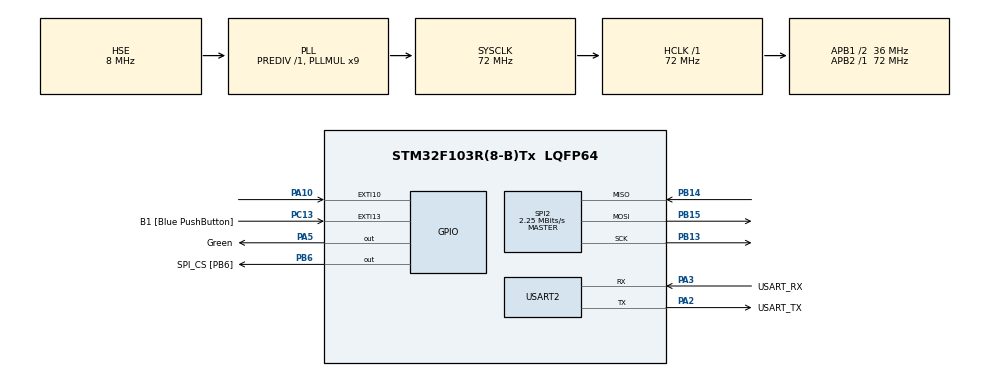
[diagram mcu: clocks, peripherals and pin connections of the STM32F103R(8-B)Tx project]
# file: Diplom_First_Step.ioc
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Dma.Request0=SPI2_RX
Dma.SPI2_RX.0.Direction=DMA_PERIPH_TO_MEMORY
Dma.SPI2_RX.0.Instance=DMA1_Channel4
Dma.SPI2_RX.0.MemDataAlignment=DMA_MDATAALIGN_HALFWORD
Dma.SPI2_RX.0.MemInc=DMA_MINC_ENABLE
Dma.SPI2_RX.0.Mode=DMA_NORMAL
Dma.SPI2_RX.0.PeriphDataAlignment=DMA_PDATAALIGN_BYTE
Dma.SPI2_RX.0.PeriphInc=DMA_PINC_DISABLE
Dma.SPI2_RX.0.Priority=DMA_PRIORITY_LOW
FREERTOS.Tasks01=defaultTask,0,2048,ADXL345_Data_Collector_Task,Default,NULL,Dynamic,NULL,NULL
FREERTOS.configTOTAL_HEAP_SIZE=16384
FREERTOS.configUSE_COUNTING_SEMAPHORES=1
FREERTOS.configUSE_NEWLIB_REENTRANT=1
Mcu.Family=STM32F1
Mcu.Name=STM32F103R(8-B)Tx
Mcu.Package=LQFP64
NVIC.DMA1_Channel4_IRQn=true\:5\:0\:false\:false\:true\:true\:false\:true
NVIC.EXTI15_10_IRQn=true\:5\:0\:false\:false\:true\:true\:true\:true
NVIC.PriorityGroup=NVIC_PRIORITYGROUP_4
NVIC.SPI2_IRQn=true\:5\:0\:false\:false\:true\:true\:true\:true
NVIC.TIM4_IRQn=true\:15\:0\:false\:false\:true\:false\:false\:true
NVIC.TimeBase=TIM4_IRQn
NVIC.TimeBaseIP=TIM4
NVIC.USART2_IRQn=true\:5\:0\:false\:false\:true\:true\:true\:true
PA10.Signal=GPXTI10
PA13.GPIO_Label=TMS
PA13.Mode=Serial_Wire
PA13.Signal=SYS_JTMS-SWDIO
PA14.GPIO_Label=TCK
PA14.Mode=Serial_Wire
PA14.Signal=SYS_JTCK-SWCLK
PA2.GPIO_Label=USART_TX
PA2.GPIO_Mode=GPIO_MODE_AF_PP
PA2.GPIO_PuPd=GPIO_NOPULL
PA2.GPIO_Speed=GPIO_SPEED_FREQ_LOW
PA2.Mode=Asynchronous
PA2.Signal=USART2_TX
PA3.GPIO_Label=USART_RX
PA3.GPIO_Mode=GPIO_MODE_AF_PP
PA3.GPIO_PuPd=GPIO_NOPULL
PA3.GPIO_Speed=GPIO_SPEED_FREQ_LOW
PA3.Mode=Asynchronous
PA3.Signal=USART2_RX
PA5.GPIO_Label=Green
PA5.Signal=GPIO_Output
PB13.Mode=Full_Duplex_Master
PB13.Signal=SPI2_SCK
PB14.Mode=Full_Duplex_Master
PB14.Signal=SPI2_MISO
PB15.Mode=Full_Duplex_Master
PB15.Signal=SPI2_MOSI
PB3.GPIO_Label=SWO
PB3.Signal=SYS_JTDO-TRACESWO
PB6.GPIO_Label=SPI_CS [PB6]
PB6.GPIO_ModeDefaultOutputPP=GPIO_MODE_OUTPUT_PP
PB6.GPIO_Speed=GPIO_SPEED_FREQ_HIGH
PB6.Signal=GPIO_Output
PC13-TAMPER-RTC.GPIO_Label=B1 [Blue PushButton]
PC13-TAMPER-RTC.GPIO_PuPd=GPIO_NOPULL
PC13-TAMPER-RTC.Signal=GPXTI13
PC14-OSC32_IN.Mode=LSE-External-Oscillator
PC14-OSC32_IN.Signal=RCC_OSC32_IN
PC15-OSC32_OUT.Mode=LSE-External-Oscillator
PC15-OSC32_OUT.Signal=RCC_OSC32_OUT
PD0-OSC_IN.Mode=HSE-External-Clock-Source
PD0-OSC_IN.Signal=RCC_OSC_IN
PD1-OSC_OUT.Mode=HSE-External-Clock-Source
PD1-OSC_OUT.Signal=RCC_OSC_OUT
ProjectManager.HeapSize=0x300
ProjectManager.StackSize=0x500
ProjectManager.TargetToolchain=STM32CubeIDE
RCC.AHBFreq_Value=72000000
RCC.APB1CLKDivider=RCC_HCLK_DIV2
RCC.APB1Freq_Value=36000000
RCC.APB1TimFreq_Value=72000000
RCC.APB2Freq_Value=72000000
RCC.APB2TimFreq_Value=72000000
RCC.HCLKFreq_Value=72000000
RCC.PLLMUL=RCC_PLL_MUL9
RCC.PLLSourceVirtual=RCC_PLLSOURCE_HSE
RCC.RTCClockSelection=RCC_RTCCLKSOURCE_LSE
RCC.SYSCLKFreq_VALUE=72000000
RCC.SYSCLKSource=RCC_SYSCLKSOURCE_PLLCLK
RCC.USBFreq_Value=72000000
SPI2.BaudRatePrescaler=SPI_BAUDRATEPRESCALER_16
SPI2.CLKPhase=SPI_PHASE_2EDGE
SPI2.CLKPolarity=SPI_POLARITY_HIGH
SPI2.CalculateBaudRate=2.25 MBits/s
SPI2.Direction=SPI_DIRECTION_2LINES
SPI2.Mode=SPI_MODE_MASTER
SPI2.VirtualType=VM_MASTER
USART2.VirtualMode=VM_ASYNC
VP_FREERTOS_VS_CMSIS_V1.Mode=CMSIS_V1
VP_SYS_VS_tim4.Mode=TIM4
board=NUCLEO-F103RB

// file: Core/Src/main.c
/* USER CODE BEGIN Header */
/**
  ******************************************************************************
  * @file           : main.c
  * @brief          : Main program body
  ******************************************************************************
  * @attention
  *
  * <h2><center>&copy; Copyright (c) 2021 STMicroelectronics.
  * All rights reserved.</center></h2>
  *
  * This software component is licensed by ST under BSD 3-Clause license,
  * the "License"; You may not use this file except in compliance with the
  * License. You may obtain a copy of the License at:
  *                        opensource.org/licenses/BSD-3-Clause
  *
  ******************************************************************************
  */
/*	Подключение акселерометра к микроконтроллеру
 * 	Акселерометр 	STM32F103RB - NUCLEO_F103RB
 * 		GND					   GND
 * 		VCC				   CN07 - PIN16
 * 		CS				   CN10 - PIN17
 * 	   INT1				   ------------
 * 	   INT2				   ------------
 * 	  	SDO				   CN10 - PIN13
 * 		SDA				   CN10 - PIN15
 * 		SCL				   CN10 - PIN11
 *
 */
/* USER CODE END Header */
#include "main.h"
#include "cmsis_os.h"

/* USER CODE BEGIN Includes */

/*	HAL_FREERTOS	*/
#include 	"uart_cobs_service.h"
#include 	"uart_freertos.h"
/*	Acceleration sensor	*/
#include 	"ADXL345.h"

#define 	Debug_Active

#ifdef 		Debug_Active
	#include 	"stdio.h"
#endif
/* USER CODE END Includes */

/* USER CODE BEGIN PD */

#define Length_Realization 		((uint16_t) 1024)

/* USER CODE END PD */

SPI_HandleTypeDef hspi2;

UART_HandleTypeDef huart2;

osThreadId defaultTaskHandle;
osSemaphoreId DataReloadInAccelerometerHandle;
/* USER CODE BEGIN PV */

ADXL_ConfigTypeDef_t 	ADXL;
uart_cobs_service_t 	Cobs_UART;

/* USER CODE END PV */

void SystemClock_Config(void);
static void MX_GPIO_Init(void);
static void MX_USART2_UART_Init(void);
static void MX_SPI2_Init(void);
void ADXL345_Data_Collector_Task(void const * argument);

/* USER CODE BEGIN PFP */
void ADXL345_Config(void);
void UART_Cobs_Config(void);
/* USER CODE END PFP */

int main(void)
{

  /* MCU Configuration--------------------------------------------------------*/

  /* Reset of all peripherals, Initializes the Flash interface and the Systick. */
  HAL_Init();

  /* Configure the system clock */
  SystemClock_Config();

  /* Initialize all configured peripherals */
  MX_GPIO_Init();
  MX_USART2_UART_Init();
  MX_SPI2_Init();
  /* USER CODE BEGIN 2 */
  /*	Deactivate IRQ then control Input and Output Transaction	*/
  /* USER CODE END 2 */

  /* Create the semaphores(s) */
  /* definition and creation of DataReloadInAccelerometer */
  osSemaphoreDef(DataReloadInAccelerometer);
  DataReloadInAccelerometerHandle = osSemaphoreCreate(osSemaphore(DataReloadInAccelerometer), 1);

  /* USER CODE BEGIN RTOS_SEMAPHORES */
  /* add semaphores, ... */
  xSemaphoreTake(DataReloadInAccelerometerHandle, portMAX_DELAY);
  /* USER CODE END RTOS_SEMAPHORES */

  /* Create the thread(s) */
  /* definition and creation of defaultTask */
  osThreadDef(defaultTask, ADXL345_Data_Collector_Task, osPriorityNormal, 0, 2048);
  defaultTaskHandle = osThreadCreate(osThread(defaultTask), NULL);

  /* USER CODE BEGIN RTOS_THREADS */
  /* add threads, ... */
  UART_Cobs_Config();
  /* USER CODE END RTOS_THREADS */

  /* Start scheduler */
  osKernelStart();

  /* We should never get here as control is now taken by the scheduler */
  /* Infinite loop */
  while (1)
  {

  }
}

void SystemClock_Config(void)
{
  RCC_OscInitTypeDef RCC_OscInitStruct = {0};
  RCC_ClkInitTypeDef RCC_ClkInitStruct = {0};

  /** Initializes the RCC Oscillators according to the specified parameters
  * in the RCC_OscInitTypeDef structure.
  */
  RCC_OscInitStruct.OscillatorType = RCC_OSCILLATORTYPE_HSE;
  RCC_OscInitStruct.HSEState = RCC_HSE_BYPASS;
  RCC_OscInitStruct.HSEPredivValue = RCC_HSE_PREDIV_DIV1;
  RCC_OscInitStruct.HSIState = RCC_HSI_ON;
  RCC_OscInitStruct.PLL.PLLState = RCC_PLL_ON;
  RCC_OscInitStruct.PLL.PLLSource = RCC_PLLSOURCE_HSE;
  RCC_OscInitStruct.PLL.PLLMUL = RCC_PLL_MUL9;
  if (HAL_RCC_OscConfig(&RCC_OscInitStruct) != HAL_OK)
  {
    Error_Handler();
  }
  /** Initializes the CPU, AHB and APB buses clocks
  */
  RCC_ClkInitStruct.ClockType = RCC_CLOCKTYPE_HCLK|RCC_CLOCKTYPE_SYSCLK
                              |RCC_CLOCKTYPE_PCLK1|RCC_CLOCKTYPE_PCLK2;
  RCC_ClkInitStruct.SYSCLKSource = RCC_SYSCLKSOURCE_PLLCLK;
  RCC_ClkInitStruct.AHBCLKDivider = RCC_SYSCLK_DIV1;
  RCC_ClkInitStruct.APB1CLKDivider = RCC_HCLK_DIV2;
  RCC_ClkInitStruct.APB2CLKDivider = RCC_HCLK_DIV1;

  if (HAL_RCC_ClockConfig(&RCC_ClkInitStruct, FLASH_LATENCY_2) != HAL_OK)
  {
    Error_Handler();
  }
}

static void MX_SPI2_Init(void)
{

  /* SPI2 parameter configuration*/
  hspi2.Instance = SPI2;
  hspi2.Init.Mode = SPI_MODE_MASTER;
  hspi2.Init.Direction = SPI_DIRECTION_2LINES;
  hspi2.Init.DataSize = SPI_DATASIZE_8BIT;
  hspi2.Init.CLKPolarity = SPI_POLARITY_HIGH;
  hspi2.Init.CLKPhase = SPI_PHASE_2EDGE;
  hspi2.Init.NSS = SPI_NSS_SOFT;
  hspi2.Init.BaudRatePrescaler = SPI_BAUDRATEPRESCALER_16;
  hspi2.Init.FirstBit = SPI_FIRSTBIT_MSB;
  hspi2.Init.TIMode = SPI_TIMODE_DISABLE;
  hspi2.Init.CRCCalculation = SPI_CRCCALCULATION_DISABLE;
  hspi2.Init.CRCPolynomial = 10;
  if (HAL_SPI_Init(&hspi2) != HAL_OK)
  {
    Error_Handler();
  }

}

static void MX_USART2_UART_Init(void)
{

  huart2.Instance = USART2;
  huart2.Init.BaudRate = 115200;
  huart2.Init.WordLength = UART_WORDLENGTH_8B;
  huart2.Init.StopBits = UART_STOPBITS_1;
  huart2.Init.Parity = UART_PARITY_NONE;
  huart2.Init.Mode = UART_MODE_TX_RX;
  huart2.Init.HwFlowCtl = UART_HWCONTROL_NONE;
  huart2.Init.OverSampling = UART_OVERSAMPLING_16;
  if (HAL_UART_Init(&huart2) != HAL_OK)
  {
    Error_Handler();
  }

}

static void MX_GPIO_Init(void)
{
  GPIO_InitTypeDef GPIO_InitStruct = {0};

  /* GPIO Ports Clock Enable */
  __HAL_RCC_GPIOC_CLK_ENABLE();
  __HAL_RCC_GPIOD_CLK_ENABLE();
  __HAL_RCC_GPIOA_CLK_ENABLE();
  __HAL_RCC_GPIOB_CLK_ENABLE();

  /*Configure GPIO pin Output Level */
  HAL_GPIO_WritePin(Green_GPIO_Port, Green_Pin, GPIO_PIN_RESET);

  /*Configure GPIO pin Output Level */
  HAL_GPIO_WritePin(SPI_CS_GPIO_Port, SPI_CS_Pin, GPIO_PIN_RESET);

  /*Configure GPIO pin : B1_Pin */
  GPIO_InitStruct.Pin = B1_Pin;
  GPIO_InitStruct.Mode = GPIO_MODE_IT_RISING;
  GPIO_InitStruct.Pull = GPIO_NOPULL;
  HAL_GPIO_Init(B1_GPIO_Port, &GPIO_InitStruct);

  /*Configure GPIO pin : Green_Pin */
  GPIO_InitStruct.Pin = Green_Pin;
  GPIO_InitStruct.Mode = GPIO_MODE_OUTPUT_PP;
  GPIO_InitStruct.Pull = GPIO_NOPULL;
  GPIO_InitStruct.Speed = GPIO_SPEED_FREQ_LOW;
  HAL_GPIO_Init(Green_GPIO_Port, &GPIO_InitStruct);

  /*Configure GPIO pin : Accelerometer_INT2_Pin */
  GPIO_InitStruct.Pin = Accelerometer_INT2_Pin;
  GPIO_InitStruct.Mode = GPIO_MODE_IT_RISING;
  GPIO_InitStruct.Pull = GPIO_NOPULL;
  HAL_GPIO_Init(Accelerometer_INT2_GPIO_Port, &GPIO_InitStruct);

  /*Configure GPIO pin : SPI_CS_Pin */
  GPIO_InitStruct.Pin = SPI_CS_Pin;
  GPIO_InitStruct.Mode = GPIO_MODE_OUTPUT_PP;
  GPIO_InitStruct.Pull = GPIO_NOPULL;
  GPIO_InitStruct.Speed = GPIO_SPEED_FREQ_HIGH;
  HAL_GPIO_Init(SPI_CS_GPIO_Port, &GPIO_InitStruct);

  /* EXTI interrupt init*/
  HAL_NVIC_SetPriority(EXTI15_10_IRQn, 5, 0);
  HAL_NVIC_EnableIRQ(EXTI15_10_IRQn);

}

/* USER CODE BEGIN 4 */
void ADXL345_Config()
{

	ADXL.PowerMode 								= 	NormalPower;
	ADXL.BWRate	 								=	BWRATE_1600;
	ADXL.WakeUpRate 							=	WakeUpRate_8;
	ADXL.AutoSleepConfig.AutoSleep 				=	AutoSleepOFF;
	ADXL.AutoSleepConfig.ThreshInact 			=	10;
	ADXL.AutoSleepConfig.TimeInact				=	10;
	ADXL.Format.Resolution 						=	RESFULL;
	ADXL.Format.Range	 						=	RANGE_16G;
	ADXL.Format.IntInvert 						=	ACTIVE_HIGH;
	ADXL.Format.SPI_Mode 						=	FORE_WIRE_MODE;
	/*Configure GPIO pin Output Level */
	HAL_GPIO_WritePin(SPI_CS_GPIO_Port, SPI_CS_Pin, GPIO_PIN_SET);
#ifdef 	Debug_Active
	ADXL_Status ADXLStatus 						= 	ADXL345_Init(&ADXL, &hspi2);
	if (ADXLStatus == ADXL_ERR)
	{
		perror("Error: Accelerometer is not found");
		while(1)
		{
		}
	}
#else
	/*	Find Accelerometer ADXL345	*/
	ADXL_Status ADXLStatus			=	ADXL_ERR;
	while(ADXLStatus		  	   ==	ADXL_ERR)
	{
		ADXLStatus 					= 	ADXL345_Init(ADXL, hspi2);
	}
#endif

	/* Interupt Configuration	*/
	ADXL345_INTMapping(INT2, DATA_READY);
	ADXL345_INTEnable(INT2, DATA_READY);

	ADXL345_MeasureON();

}

void UART_Cobs_Config(void)
{

	uart_cobs_service_tx_create(					"Task_uart_cobs_service_tx",
													osPriorityNormal,
													0,
													724,
													&Cobs_UART
								);
	Cobs_UART.huart 								=	(uart_freertos_t*) pvPortMalloc(sizeof(uart_freertos_t));
	uart_freertos_init(								Cobs_UART.huart
					  );
	Cobs_UART.max_frame_size 						=	(size_t) Length_Realization;
	Cobs_UART.huart -> huart						=	(UART_HandleTypeDef *) &huart2;
	Cobs_UART.queue_depth 							=	1;
	Cobs_UART.mode 									=	UART_COBS_INTERRUPT;

}

void HAL_GPIO_EXTI_Callback(uint16_t GPIO_Pin)
{
	if (GPIO_Pin == Accelerometer_INT2_Pin)
	{
		xSemaphoreGiveFromISR(DataReloadInAccelerometerHandle, NULL);
	}
}

/* USER CODE END 4 */

void ADXL345_Data_Collector_Task(void const * argument)
{
  /* USER CODE BEGIN 5 */

	ADXL345_Config();

	float	Signal[Length_Realization] 				=	{0};

	ADXL.Length_Buf_Completed 						=	0;

	/* Infinite loop */
	for(uint16_t Index_Count = 0;; Index_Count++)
	{
		//	Записать данные в очередь, когда буфер переполниться
		if (Index_Count > Length_Realization)
		{
			Index_Count = 0;
			uart_cobs_send(&Cobs_UART, &Signal, Length_Realization, 10 * portTICK_PERIOD_MS);
		}
		xSemaphoreTake(DataReloadInAccelerometerHandle, portMAX_DELAY);

		Signal[Index_Count]	=	ADXL345_GetGValue(Yaxis);

	}
  /* USER CODE END 5 */
}

void HAL_TIM_PeriodElapsedCallback(TIM_HandleTypeDef *htim)
{
  if (htim->Instance == TIM4) {
    HAL_IncTick();
  }
}

void Error_Handler(void)
{
  __disable_irq();
  while (1)
  {
  }
}

/************************ (C) COPYRIGHT STMicroelectronics *****END OF FILE****/
